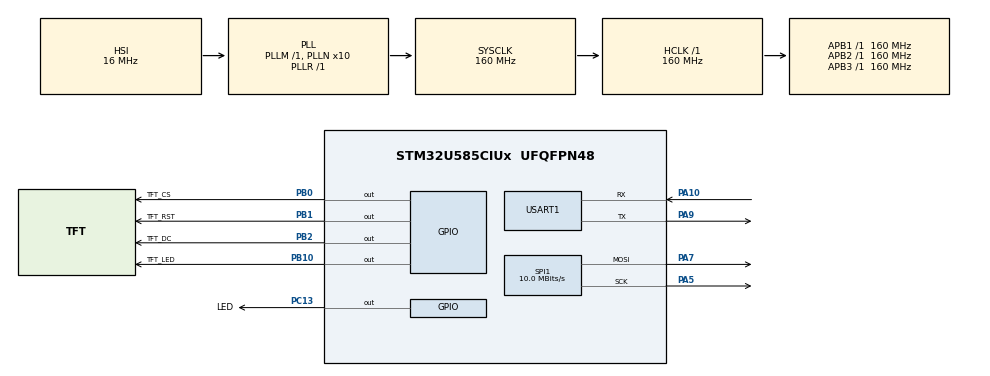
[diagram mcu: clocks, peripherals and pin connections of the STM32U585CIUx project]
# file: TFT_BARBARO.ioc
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CORTEX_M33_NS.userName=CORTEX_M33
Mcu.Family=STM32U5
Mcu.Name=STM32U585CIUx
Mcu.Package=UFQFPN48
NVIC.PriorityGroup=NVIC_PRIORITYGROUP_4
PA10.Mode=Asynchronous
PA10.Signal=USART1_RX
PA5.Mode=TX_Only_Simplex_Unidirect_Master
PA5.Signal=SPI1_SCK
PA7.Mode=TX_Only_Simplex_Unidirect_Master
PA7.Signal=SPI1_MOSI
PA9.Mode=Asynchronous
PA9.Signal=USART1_TX
PB0.GPIO_Label=TFT_CS
PB0.Signal=GPIO_Output
PB1.GPIO_Label=TFT_RST
PB1.Signal=GPIO_Output
PB10.GPIO_Label=TFT_LED
PB10.PinState=GPIO_PIN_SET
PB10.Signal=GPIO_Output
PB2.GPIO_Label=TFT_DC
PB2.Signal=GPIO_Output
PC13.GPIO_Label=LED
PC13.Signal=GPIO_Output
PH0-OSC_IN\ (PH0).Mode=HSE-External-Oscillator
PH0-OSC_IN\ (PH0).Signal=RCC_OSC_IN
PH1-OSC_OUT\ (PH1).Mode=HSE-External-Oscillator
PH1-OSC_OUT\ (PH1).Signal=RCC_OSC_OUT
ProjectManager.HeapSize=0x200
ProjectManager.StackSize=0x400
ProjectManager.TargetToolchain=STM32CubeIDE
RCC.ADCFreq_Value=16000000
RCC.AHBFreq_Value=160000000
RCC.APB1Freq_Value=160000000
RCC.APB1TimFreq_Value=160000000
RCC.APB2Freq_Value=160000000
RCC.APB2TimFreq_Value=160000000
RCC.APB3Freq_Value=160000000
RCC.CortexFreq_Value=160000000
RCC.EPOD_VALUE=16000000
RCC.HCLKFreq_Value=160000000
RCC.HSE_VALUE=25000000
RCC.HSI48_VALUE=48000000
RCC.HSI_VALUE=16000000
RCC.LSE_VALUE=32768
RCC.LSIDIV_VALUE=32000
RCC.MSIClockRange=RCC_MSIRANGE_0
RCC.MSI_VALUE=48000000
RCC.PLL1R=1
RCC.PLL2FRACN=0
RCC.PLL3FRACN=0
RCC.PLLFRACN=0
RCC.PLLN=10
RCC.PLLSourceVirtual=RCC_PLLSOURCE_HSI
RCC.SYSCLKFreq_VALUE=160000000
RCC.SYSCLKSource=RCC_SYSCLKSOURCE_PLLCLK
RCC.USBFreq_Value=48000000
RCC.VCOOutputFreq_Value=160000000
SPI1.BaudRatePrescaler=SPI_BAUDRATEPRESCALER_16
SPI1.CalculateBaudRate=10.0 MBits/s
SPI1.DataSize=SPI_DATASIZE_8BIT
SPI1.Direction=SPI_DIRECTION_2LINES_TXONLY
SPI1.Mode=SPI_MODE_MASTER
SPI1.VirtualType=VM_MASTER
USART1.VirtualMode-Asynchronous=VM_ASYNC
VP_ICACHE_VS_ICACHE.Mode=DefaultMode
VP_LPBAMQUEUE_VS_QUEUE.Mode=QUEUEMODE
VP_LPBAM_VS_SIG1.Mode=SmartRun
VP_LPBAM_VS_SIG4.Mode=LPDMA1
VP_MEMORYMAP_VS_MEMORYMAP.Mode=CurAppReg
VP_PWR_VS_SECSignals.Mode=Security/Privilege
board=custom

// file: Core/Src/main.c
/* USER CODE BEGIN Header */
/**
  ******************************************************************************
  * @file           : main.c
  * @brief          : Main program body
  ******************************************************************************
  * @attention
  *
  * Copyright (c) 2025 STMicroelectronics.
  * All rights reserved.
  *
  * This software is licensed under terms that can be found in the LICENSE file
  * in the root directory of this software component.
  * If no LICENSE file comes with this software, it is provided AS-IS.
  *
  ******************************************************************************
  */
/* USER CODE END Header */
#include "main.h"

/* USER CODE BEGIN Includes */
#include "ili9488.h"
#include "fonts.h"
#include "imagenes.h"
#include "DASHBOARD.h"
/* USER CODE END Includes */

SPI_HandleTypeDef hspi1;

UART_HandleTypeDef huart1;

/* USER CODE BEGIN PV */
uint8_t  datos[]="ALCIDES";
/* USER CODE END PV */

void SystemClock_Config(void);
static void MX_GPIO_Init(void);
static void MX_SPI1_Init(void);
static void MX_USART1_UART_Init(void);
static void MX_ICACHE_Init(void);

int main(void)
{

  /* MCU Configuration--------------------------------------------------------*/

  /* Reset of all peripherals, Initializes the Flash interface and the Systick. */
  HAL_Init();

  /* Configure the system clock */
  SystemClock_Config();

  /* Initialize all configured peripherals */
  MX_GPIO_Init();
  MX_SPI1_Init();
  MX_USART1_UART_Init();
  MX_ICACHE_Init();
  /* USER CODE BEGIN 2 */
  ILI9488_Init();

setRotation(horizontal);

 fillScreen(ILI9488_RED);

 draw_bitmap(0, 0, 1, tigr1`q`1e);
 HAL_Delay(2000);
 setRotation(vertical);

 draw_bitmap(0, 0, 1, Dobby);

 // draw_string(150, 280, "ALCIDES", COLOR_RED, font4);

  /* USER CODE END 2 */

  /* Infinite loop */
  /* USER CODE BEGIN WHILE */
  while (1)
  {
   HAL_GPIO_TogglePin(LED_GPIO_Port, LED_Pin);
   HAL_Delay(200);
    /* USER CODE END WHILE */

  }
}

void SystemClock_Config(void)
{
  RCC_OscInitTypeDef RCC_OscInitStruct = {0};
  RCC_ClkInitTypeDef RCC_ClkInitStruct = {0};

  /** Configure the main internal regulator output voltage
  */
  if (HAL_PWREx_ControlVoltageScaling(PWR_REGULATOR_VOLTAGE_SCALE1) != HAL_OK)
  {
    Error_Handler();
  }

  /** Initializes the CPU, AHB and APB buses clocks
  */
  RCC_OscInitStruct.OscillatorType = RCC_OSCILLATORTYPE_HSI;
  RCC_OscInitStruct.HSIState = RCC_HSI_ON;
  RCC_OscInitStruct.HSICalibrationValue = RCC_HSICALIBRATION_DEFAULT;
  RCC_OscInitStruct.PLL.PLLState = RCC_PLL_ON;
  RCC_OscInitStruct.PLL.PLLSource = RCC_PLLSOURCE_HSI;
  RCC_OscInitStruct.PLL.PLLMBOOST = RCC_PLLMBOOST_DIV1;
  RCC_OscInitStruct.PLL.PLLM = 1;
  RCC_OscInitStruct.PLL.PLLN = 10;
  RCC_OscInitStruct.PLL.PLLP = 2;
  RCC_OscInitStruct.PLL.PLLQ = 2;
  RCC_OscInitStruct.PLL.PLLR = 1;
  RCC_OscInitStruct.PLL.PLLRGE = RCC_PLLVCIRANGE_1;
  RCC_OscInitStruct.PLL.PLLFRACN = 0;
  if (HAL_RCC_OscConfig(&RCC_OscInitStruct) != HAL_OK)
  {
    Error_Handler();
  }

  /** Initializes the CPU, AHB and APB buses clocks
  */
  RCC_ClkInitStruct.ClockType = RCC_CLOCKTYPE_HCLK|RCC_CLOCKTYPE_SYSCLK
                              |RCC_CLOCKTYPE_PCLK1|RCC_CLOCKTYPE_PCLK2
                              |RCC_CLOCKTYPE_PCLK3;
  RCC_ClkInitStruct.SYSCLKSource = RCC_SYSCLKSOURCE_PLLCLK;
  RCC_ClkInitStruct.AHBCLKDivider = RCC_SYSCLK_DIV1;
  RCC_ClkInitStruct.APB1CLKDivider = RCC_HCLK_DIV1;
  RCC_ClkInitStruct.APB2CLKDivider = RCC_HCLK_DIV1;
  RCC_ClkInitStruct.APB3CLKDivider = RCC_HCLK_DIV1;

  if (HAL_RCC_ClockConfig(&RCC_ClkInitStruct, FLASH_LATENCY_4) != HAL_OK)
  {
    Error_Handler();
  }
}

static void MX_ICACHE_Init(void)
{

  /** Enable instruction cache (default 2-ways set associative cache)
  */
  if (HAL_ICACHE_Enable() != HAL_OK)
  {
    Error_Handler();
  }

}

static void MX_SPI1_Init(void)
{

  SPI_AutonomousModeConfTypeDef HAL_SPI_AutonomousMode_Cfg_Struct = {0};

  /* SPI1 parameter configuration*/
  hspi1.Instance = SPI1;
  hspi1.Init.Mode = SPI_MODE_MASTER;
  hspi1.Init.Direction = SPI_DIRECTION_2LINES_TXONLY;
  hspi1.Init.DataSize = SPI_DATASIZE_8BIT;
  hspi1.Init.CLKPolarity = SPI_POLARITY_LOW;
  hspi1.Init.CLKPhase = SPI_PHASE_1EDGE;
  hspi1.Init.NSS = SPI_NSS_SOFT;
  hspi1.Init.BaudRatePrescaler = SPI_BAUDRATEPRESCALER_16;
  hspi1.Init.FirstBit = SPI_FIRSTBIT_MSB;
  hspi1.Init.TIMode = SPI_TIMODE_DISABLE;
  hspi1.Init.CRCCalculation = SPI_CRCCALCULATION_DISABLE;
  hspi1.Init.CRCPolynomial = 0x7;
  hspi1.Init.NSSPMode = SPI_NSS_PULSE_ENABLE;
  hspi1.Init.NSSPolarity = SPI_NSS_POLARITY_LOW;
  hspi1.Init.FifoThreshold = SPI_FIFO_THRESHOLD_01DATA;
  hspi1.Init.MasterSSIdleness = SPI_MASTER_SS_IDLENESS_00CYCLE;
  hspi1.Init.MasterInterDataIdleness = SPI_MASTER_INTERDATA_IDLENESS_00CYCLE;
  hspi1.Init.MasterReceiverAutoSusp = SPI_MASTER_RX_AUTOSUSP_DISABLE;
  hspi1.Init.MasterKeepIOState = SPI_MASTER_KEEP_IO_STATE_DISABLE;
  hspi1.Init.IOSwap = SPI_IO_SWAP_DISABLE;
  hspi1.Init.ReadyMasterManagement = SPI_RDY_MASTER_MANAGEMENT_INTERNALLY;
  hspi1.Init.ReadyPolarity = SPI_RDY_POLARITY_HIGH;
  if (HAL_SPI_Init(&hspi1) != HAL_OK)
  {
    Error_Handler();
  }
  HAL_SPI_AutonomousMode_Cfg_Struct.TriggerState = SPI_AUTO_MODE_DISABLE;
  HAL_SPI_AutonomousMode_Cfg_Struct.TriggerSelection = SPI_GRP1_GPDMA_CH0_TCF_TRG;
  HAL_SPI_AutonomousMode_Cfg_Struct.TriggerPolarity = SPI_TRIG_POLARITY_RISING;
  if (HAL_SPIEx_SetConfigAutonomousMode(&hspi1, &HAL_SPI_AutonomousMode_Cfg_Struct) != HAL_OK)
  {
    Error_Handler();
  }

}

static void MX_USART1_UART_Init(void)
{

  huart1.Instance = USART1;
  huart1.Init.BaudRate = 115200;
  huart1.Init.WordLength = UART_WORDLENGTH_8B;
  huart1.Init.StopBits = UART_STOPBITS_1;
  huart1.Init.Parity = UART_PARITY_NONE;
  huart1.Init.Mode = UART_MODE_TX_RX;
  huart1.Init.HwFlowCtl = UART_HWCONTROL_NONE;
  huart1.Init.OverSampling = UART_OVERSAMPLING_16;
  huart1.Init.OneBitSampling = UART_ONE_BIT_SAMPLE_DISABLE;
  huart1.Init.ClockPrescaler = UART_PRESCALER_DIV1;
  huart1.AdvancedInit.AdvFeatureInit = UART_ADVFEATURE_NO_INIT;
  if (HAL_UART_Init(&huart1) != HAL_OK)
  {
    Error_Handler();
  }
  if (HAL_UARTEx_SetTxFifoThreshold(&huart1, UART_TXFIFO_THRESHOLD_1_8) != HAL_OK)
  {
    Error_Handler();
  }
  if (HAL_UARTEx_SetRxFifoThreshold(&huart1, UART_RXFIFO_THRESHOLD_1_8) != HAL_OK)
  {
    Error_Handler();
  }
  if (HAL_UARTEx_DisableFifoMode(&huart1) != HAL_OK)
  {
    Error_Handler();
  }

}

static void MX_GPIO_Init(void)
{
  GPIO_InitTypeDef GPIO_InitStruct = {0};

  /* GPIO Ports Clock Enable */
  __HAL_RCC_GPIOC_CLK_ENABLE();
  __HAL_RCC_GPIOH_CLK_ENABLE();
  __HAL_RCC_GPIOA_CLK_ENABLE();
  __HAL_RCC_GPIOB_CLK_ENABLE();

  /*Configure GPIO pin Output Level */
  HAL_GPIO_WritePin(LED_GPIO_Port, LED_Pin, GPIO_PIN_RESET);

  /*Configure GPIO pin Output Level */
  HAL_GPIO_WritePin(GPIOB, TFT_CS_Pin|TFT_RST_Pin|TFT_DC_Pin, GPIO_PIN_RESET);

  /*Configure GPIO pin Output Level */
  HAL_GPIO_WritePin(TFT_LED_GPIO_Port, TFT_LED_Pin, GPIO_PIN_SET);

  /*Configure GPIO pin : LED_Pin */
  GPIO_InitStruct.Pin = LED_Pin;
  GPIO_InitStruct.Mode = GPIO_MODE_OUTPUT_PP;
  GPIO_InitStruct.Pull = GPIO_NOPULL;
  GPIO_InitStruct.Speed = GPIO_SPEED_FREQ_LOW;
  HAL_GPIO_Init(LED_GPIO_Port, &GPIO_InitStruct);

  /*Configure GPIO pins : TFT_CS_Pin TFT_RST_Pin TFT_DC_Pin TFT_LED_Pin */
  GPIO_InitStruct.Pin = TFT_CS_Pin|TFT_RST_Pin|TFT_DC_Pin|TFT_LED_Pin;
  GPIO_InitStruct.Mode = GPIO_MODE_OUTPUT_PP;
  GPIO_InitStruct.Pull = GPIO_NOPULL;
  GPIO_InitStruct.Speed = GPIO_SPEED_FREQ_LOW;
  HAL_GPIO_Init(GPIOB, &GPIO_InitStruct);

}

void Error_Handler(void)
{
  __disable_irq();
  while (1)
  {
  }
}
